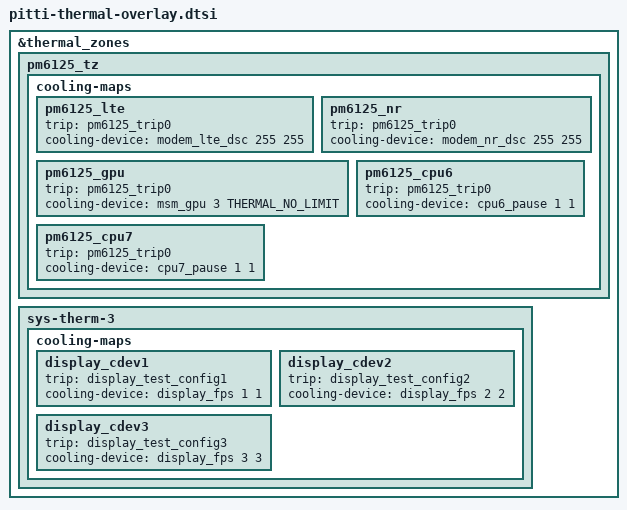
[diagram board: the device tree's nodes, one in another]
#include <dt-bindings/thermal/thermal_qti.h>

&thermal_zones {
	pm6125_tz {
		cooling-maps {
			pm6125_lte {
				trip = <&pm6125_trip0>;
				cooling-device = <&modem_lte_dsc 255 255>;
			};

			pm6125_nr {
				trip = <&pm6125_trip0>;
				cooling-device = <&modem_nr_dsc 255 255>;
			};

			pm6125_gpu {
				trip = <&pm6125_trip0>;
				cooling-device = <&msm_gpu 3 THERMAL_NO_LIMIT>;
			};

			pm6125_cpu6 {
				trip = <&pm6125_trip0>;
				cooling-device = <&cpu6_pause 1 1>;
			};

			pm6125_cpu7 {
				trip = <&pm6125_trip0>;
				cooling-device = <&cpu7_pause 1 1>;
			};
		};
	};

	sys-therm-3 {
		cooling-maps {
			display_cdev1 {
				trip = <&display_test_config1>;
				cooling-device = <&display_fps 1 1>;
			};

			display_cdev2 {
				trip = <&display_test_config2>;
				cooling-device = <&display_fps 2 2>;
			};

			display_cdev3 {
				trip = <&display_test_config3>;
				cooling-device = <&display_fps 3 3>;
			};
		};
	};
};
